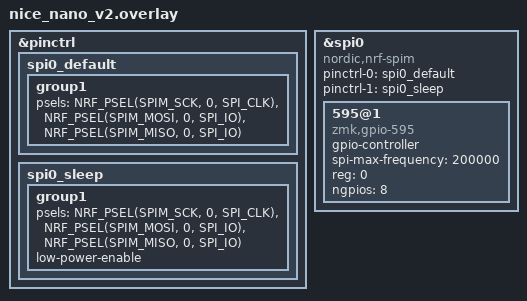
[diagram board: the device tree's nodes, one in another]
#include <dt-bindings/led/led.h>
#include "../spi_pins.h"

&pinctrl {
    spi0_default: spi0_default {
            group1 {
                psels = <NRF_PSEL(SPIM_SCK, 0, SPI_CLK)>,
                    <NRF_PSEL(SPIM_MOSI, 0, SPI_IO)>,
                    <NRF_PSEL(SPIM_MISO, 0, SPI_IO)>;
            };
        };

        spi0_sleep: spi0_sleep {
            group1 {
                psels = <NRF_PSEL(SPIM_SCK, 0, SPI_CLK)>,
                    <NRF_PSEL(SPIM_MOSI, 0, SPI_IO)>,
                    <NRF_PSEL(SPIM_MISO, 0, SPI_IO)>;
                low-power-enable;
            };
        };
};

#include <zephyr/dt-bindings/input/input-event-codes.h>

&spi0 {
    status = "okay";
    compatible = "nordic,nrf-spim";
    pinctrl-0 = <&spi0_default>;
    pinctrl-1 = <&spi0_sleep>;
    pinctrl-names = "default", "sleep";
    cs-gpios =
        <&gpio1 SPI_CS_TB GPIO_ACTIVE_LOW>,  //P1.04
        <&gpio1 SPI_CS_COL GPIO_ACTIVE_LOW>, //P1.00

//    trackball: trackball@0 {
//        status = "okay";
//        compatible = "pixart,pmw3610";
//        reg = <0>;
//        spi-max-frequency = <2000000>;
//        irq-gpios = <&gpio0 SPI_TB_MOT (GPIO_ACTIVE_LOW | GPIO_PULL_UP)>; //P0.06
//        cpi = <600>;
//        // swap-xy; /* optional */
//        // invert-x; /* optional */
//        // invert-y; /* optional */
//        evt-type = <INPUT_EV_REL>;
//        x-input-code = <INPUT_REL_X>;
//        y-input-code = <INPUT_REL_Y>;
//
//        force-awake;
//        /* keep the sensor awake while ZMK activity state is ACTIVE,
//           fallback to normal downshift mode after ZMK goes into IDLE / SLEEP mode.
//           thus, the sensor would be a `wakeup-source` */
//
//        force-awake-4ms-mode;
//        /* while force-awake is acitvated, enable this mode to force sampling per
//           4ms, where the default sampling rate is 8ms. */
//        /* NOTE: apply this mode if you need 250Hz with direct USB connection. */
//    };

    shifter_col: 595@1 {
            compatible = "zmk,gpio-595";
            status = "okay";
            gpio-controller;
            spi-max-frequency = <200000>;
            reg = <0>;
            #gpio-cells = <2>;
            ngpios = <8>;
        };
};

/// {
//  trackball_listener {
//    compatible = "zmk,input-listener";
//    device = <&trackball>;
//  };
//};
